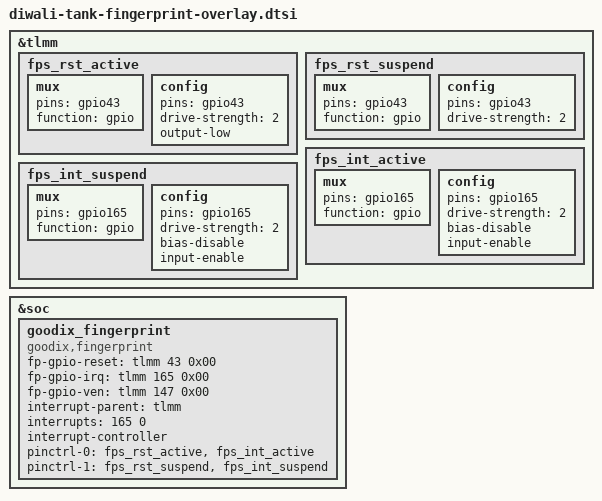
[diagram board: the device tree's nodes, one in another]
&tlmm {
	fps_rst_active: fps_rst_active {
                /* active state */
                mux {
                        pins = "gpio43";
                        function = "gpio";
                };

                config {
                        pins = "gpio43";
                        drive-strength = <2>; /* 2 MA */
                        output-low;
                };
        };

        fps_rst_suspend: fps_rst_suspend {
                /* sleep state */
                mux {
                        pins = "gpio43";
                        function = "gpio";
                };

                config {
                        pins = "gpio43";
                        drive-strength = <2>; /* 2 MA */
                };
        };

        fps_int_active: fps_int_active {
                /* active state */
                mux {
                        pins = "gpio165";
                        function = "gpio";
                };

                config {
                        pins = "gpio165";
                        drive-strength = <2>; /* 2 MA */
                        bias-disable;
                        input-enable;
                };
        };

        fps_int_suspend: fps_int_suspend {
                /* sleep state */
                mux {
                        pins = "gpio165";
                        function = "gpio";
                };

                config {
                        pins = "gpio165";
                        drive-strength = <2>; /* 2 MA */
                        bias-disable;
                        input-enable;
                };
        };
};

&soc {
	goodix_fingerprint {
		compatible = "goodix,fingerprint";
		status = "ok";
		fp-gpio-reset = <&tlmm 43 0x00>;
		fp-gpio-irq = <&tlmm 165 0x00>;
		fp-gpio-ven = <&tlmm 147 0x00>;
		interrupt-parent = <&tlmm>;
		interrupts = <165 0>;
		interrupt-controller;
		pinctrl-names = "default", "suspend";
		pinctrl-0 = <&fps_rst_active &fps_int_active>;
		pinctrl-1 = <&fps_rst_suspend &fps_int_suspend>;
	};
};
